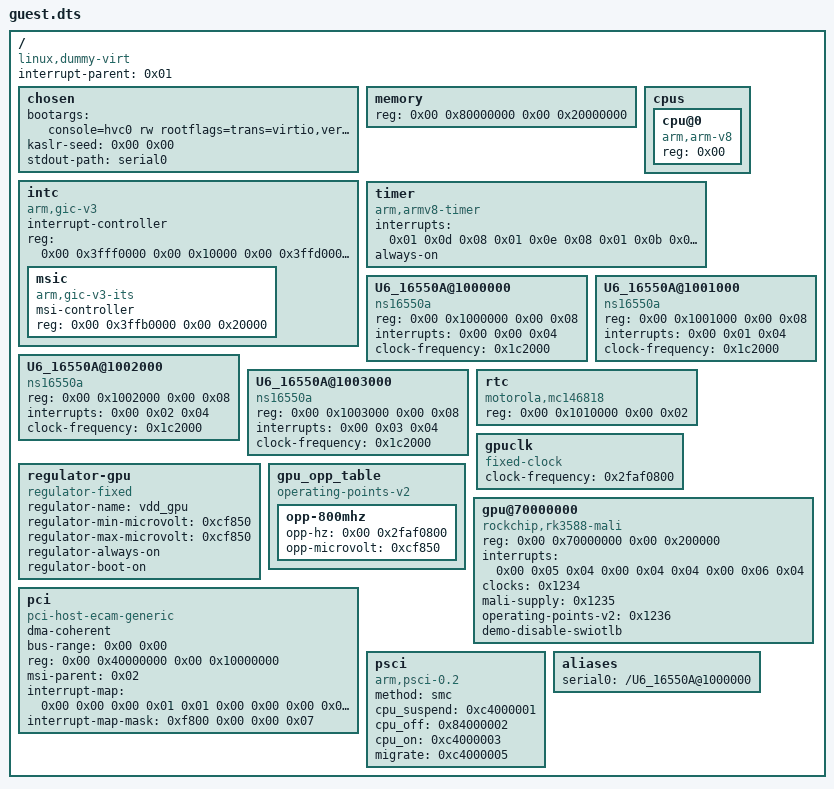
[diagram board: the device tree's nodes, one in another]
/dts-v1/;

/ {
	interrupt-parent = <0x01>;
	compatible = "linux,dummy-virt";
	#address-cells = <0x02>;
	#size-cells = <0x02>;

	chosen {
		bootargs = " console=hvc0 rw rootflags=trans=virtio,version=9p2000.L,cache=loose rootfstype=9p init=/virt/init  ip=dhcp nokaslr console=hvc0 ip=192.168.33.2::192.168.33.1:255.255.255.0::eth0:off";
		kaslr-seed = <0x00 0x00>;
		stdout-path = "serial0";
	};

	memory {
		device_type = "memory";
		reg = <0x00 0x80000000 0x00 0x20000000>;
	};

	cpus {
		#address-cells = <0x01>;
		#size-cells = <0x00>;

		cpu@0 {
			device_type = "cpu";
			compatible = "arm,arm-v8";
			reg = <0x00>;
		};
	};

	intc {
		compatible = "arm,gic-v3";
		#interrupt-cells = <0x03>;
		interrupt-controller;
		reg = <0x00 0x3fff0000 0x00 0x10000 0x00 0x3ffd0000 0x00 0x20000>;
		phandle = <0x01>;
		#address-cells = <0x02>;
		#size-cells = <0x02>;
		ranges;

		msic {
			compatible = "arm,gic-v3-its";
			msi-controller;
			phandle = <0x02>;
			reg = <0x00 0x3ffb0000 0x00 0x20000>;
		};
	};

	timer {
		compatible = "arm,armv8-timer\0arm,armv7-timer";
		interrupts = <0x01 0x0d 0x08 0x01 0x0e 0x08 0x01 0x0b 0x08 0x01 0x0a 0x08>;
		always-on;
	};

	U6_16550A@1000000 {
		compatible = "ns16550a";
		reg = <0x00 0x1000000 0x00 0x08>;
		interrupts = <0x00 0x00 0x04>;
		clock-frequency = <0x1c2000>;
	};

	U6_16550A@1001000 {
		compatible = "ns16550a";
		reg = <0x00 0x1001000 0x00 0x08>;
		interrupts = <0x00 0x01 0x04>;
		clock-frequency = <0x1c2000>;
	};

	U6_16550A@1002000 {
		compatible = "ns16550a";
		reg = <0x00 0x1002000 0x00 0x08>;
		interrupts = <0x00 0x02 0x04>;
		clock-frequency = <0x1c2000>;
	};

	U6_16550A@1003000 {
		compatible = "ns16550a";
		reg = <0x00 0x1003000 0x00 0x08>;
		interrupts = <0x00 0x03 0x04>;
		clock-frequency = <0x1c2000>;
	};

	rtc {
		compatible = "motorola,mc146818";
		reg = <0x00 0x1010000 0x00 0x02>;
	};

	gpuclk {
		compatible = "fixed-clock";
		clock-frequency = <0x2faf0800>;
		#clock-cells = <0x00>;
		phandle = <0x1234>;
	};

	regulator-gpu {
		phandle = <0x1235>;
		compatible = "regulator-fixed";
		regulator-name = "vdd_gpu";
		regulator-min-microvolt = <0xcf850>;
		regulator-max-microvolt = <0xcf850>;
		regulator-always-on;
		regulator-boot-on;
	};

	gpu_opp_table {
		compatible = "operating-points-v2";
		phandle = <0x1236>;

		opp-800mhz {
			opp-hz = <0x00 0x2faf0800>;
			opp-microvolt = <0xcf850>;
		};
	};

	gpu@70000000 {
		compatible = "rockchip,rk3588-mali\0arm,mali-valhall";
		reg = <0x00 0x70000000 0x00 0x200000>;
		interrupts = <0x00 0x05 0x04 0x00 0x04 0x04 0x00 0x06 0x04>;
		clocks = <0x1234>;
		mali-supply = <0x1235>;
		clock-names = "core";
		operating-points-v2 = <0x1236>;
		interrupt-names = "job\0mmu\0gpu";
		demo-disable-swiotlb;
	};

	pci {
		device_type = "pci";
		#address-cells = <0x03>;
		#size-cells = <0x02>;
		#interrupt-cells = <0x01>;
		compatible = "pci-host-ecam-generic";
		dma-coherent;
		bus-range = <0x00 0x00>;
		reg = <0x00 0x40000000 0x00 0x10000000>;
		ranges = <0x1000000 0x00 0x00 0x00 0x00 0x00 0x10000 0x2000000 0x00 0x50000000 0x00 0x50000000 0x00 0x30000000>;
		msi-parent = <0x02>;
		interrupt-map = <0x00 0x00 0x00 0x01 0x01 0x00 0x00 0x00 0x07 0x04 0x800 0x00 0x00 0x01 0x01 0x00 0x00 0x00 0x08 0x04 0x1000 0x00 0x00 0x01 0x01 0x00 0x00 0x00 0x09 0x04 0x1800 0x00 0x00 0x01 0x01 0x00 0x00 0x00 0x0a 0x04 0x2000 0x00 0x00 0x01 0x01 0x00 0x00 0x00 0x0b 0x04>;
		interrupt-map-mask = <0xf800 0x00 0x00 0x07>;
	};

	psci {
		compatible = "arm,psci-0.2\0arm,psci";
		method = "smc";
		cpu_suspend = <0xc4000001>;
		cpu_off = <0x84000002>;
		cpu_on = <0xc4000003>;
		migrate = <0xc4000005>;
	};

	aliases {
		serial0 = "/U6_16550A@1000000";
	};
};
